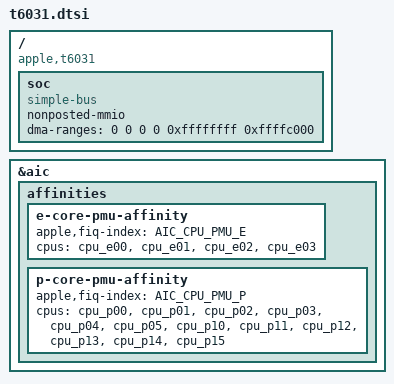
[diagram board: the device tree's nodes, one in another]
// SPDX-License-Identifier: GPL-2.0+ OR MIT
/*
 * Apple T6031 "M3 Max" SoC
 *
 * Copyright The Asahi Linux Contributors
 */

#include <dt-bindings/gpio/gpio.h>
#include <dt-bindings/interrupt-controller/apple-aic.h>
#include <dt-bindings/interrupt-controller/irq.h>
#include <dt-bindings/pinctrl/apple.h>
#include <dt-bindings/phy/phy.h>
#include <dt-bindings/spmi/spmi.h>

#include "multi-die-cpp.h"

#include "t6031-base.dtsi"

/ {
	compatible = "apple,t6031", "apple,arm-platform";

	#address-cells = <2>;
	#size-cells = <2>;

	soc: soc {
		compatible = "simple-bus";
		#address-cells = <2>;
		#size-cells = <2>;

		ranges;
		nonposted-mmio;
		/* Required to get >32-bit DMA via DARTs */
		dma-ranges = <0 0 0 0 0xffffffff 0xffffc000>;

		// filled via templated includes at the end of the file
	};
};

#define DIE
#define DIE_NO 0

&soc {
	#include "t6031-die0.dtsi"
	#include "t6031-dieX.dtsi"
	#include "t6031-nvme.dtsi"
};

#include "t6031-gpio-pins.dtsi"
#include "t6031-pmgr.dtsi"

#undef DIE
#undef DIE_NO


&aic {
	affinities {
		e-core-pmu-affinity {
			apple,fiq-index = <AIC_CPU_PMU_E>;
			cpus = <&cpu_e00 &cpu_e01 &cpu_e02 &cpu_e03>;
		};

		p-core-pmu-affinity {
			apple,fiq-index = <AIC_CPU_PMU_P>;
			cpus = <&cpu_p00 &cpu_p01 &cpu_p02 &cpu_p03 &cpu_p04 &cpu_p05
				&cpu_p10 &cpu_p11 &cpu_p12 &cpu_p13 &cpu_p14 &cpu_p15>;
		};
	};
};
